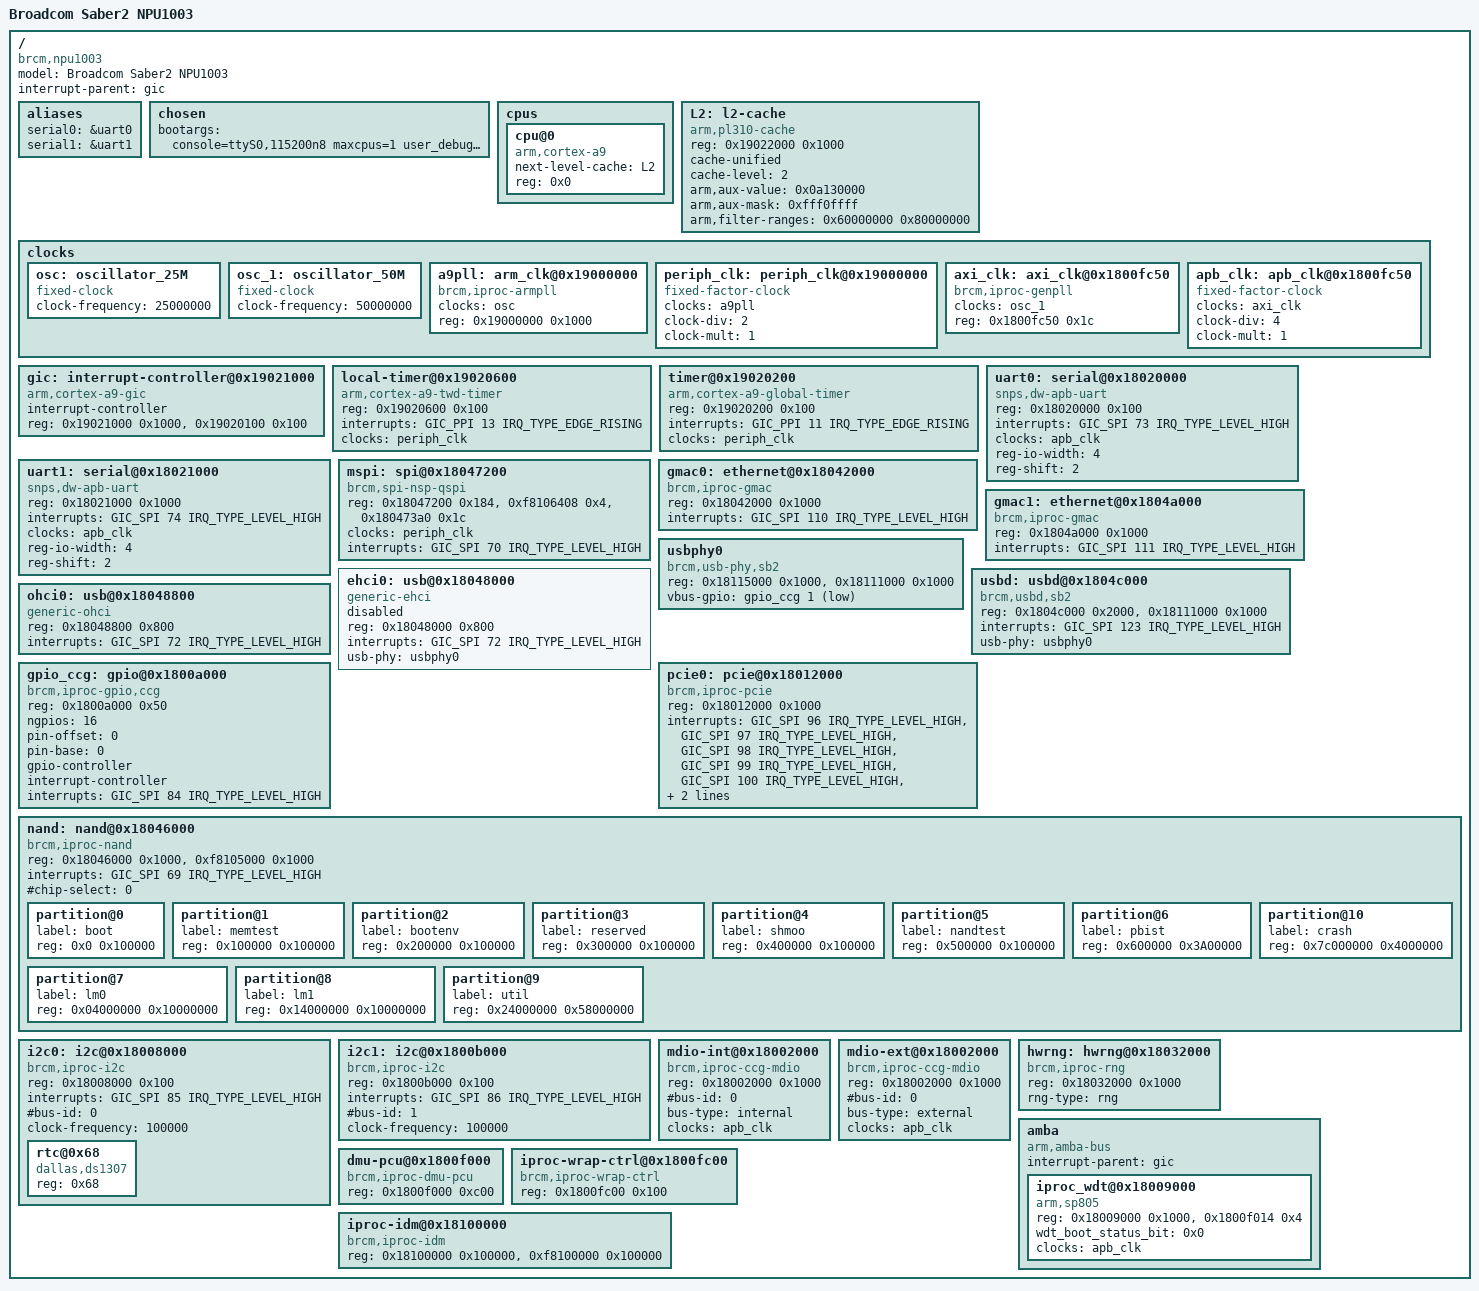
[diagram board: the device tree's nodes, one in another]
/*
 SB2 DTS
*/

/dts-v1/;

#include <dt-bindings/interrupt-controller/arm-gic.h>
#include <dt-bindings/gpio/gpio.h>
#include "skeleton.dtsi"

/ {
	model = "Broadcom Saber2 NPU1003";
	compatible = "brcm,npu1003", "brcm,iproc-p7";
	interrupt-parent = <&gic>;

	aliases {
		serial0 = &uart0;
		serial1 = &uart1;
	};

	chosen {
	bootargs = "console=ttyS0,115200n8 maxcpus=1 user_debug=31 envaddr=0xe0200000";
	};

	cpus {
		#address-cells = <1>;
		#size-cells = <0>;

		cpu@0 {
			device_type = "cpu";
			compatible = "arm,cortex-a9";
			next-level-cache = <&L2>;
			reg = <0x0>;
		};
	};

  	L2: l2-cache {
		compatible = "arm,pl310-cache";
		reg = <0x19022000 0x1000>;
		cache-unified;
		cache-level = <2>;
		/* aux register value */
		arm,aux-value = <0x0a130000>;
		arm,aux-mask = <0xfff0ffff>;
		arm,filter-ranges = <0x60000000 0x80000000>;
		/*arm,data-latency = <2 2 2>;*/
		/*arm,tag-latency = <1 1 1>;*/
	};

  	clocks {
		#address-cells = <1>;
		#size-cells = <1>;
		ranges;

		osc: oscillator_25M {
			#clock-cells = <0>;
			compatible = "fixed-clock";
			clock-frequency = <25000000>;
		};

		osc_1: oscillator_50M {
			#clock-cells = <0>;
			compatible = "fixed-clock";
			clock-frequency = <50000000>;
		};

		a9pll: arm_clk@0x19000000 {
			#clock-cells = <0>;
			compatible = "brcm,iproc-armpll";
			clocks = <&osc>;
			reg = <0x19000000 0x1000>;
		};

		periph_clk: periph_clk@0x19000000 {
			#clock-cells = <0>;
			compatible = "fixed-factor-clock";
			clocks = <&a9pll>;
			clock-div = <2>;
			clock-mult = <1>;
		};

		axi_clk: axi_clk@0x1800fc50 {
			#clock-cells = <0>;
			compatible = "brcm,iproc-genpll";
			clocks = <&osc_1>;
			reg = <0x1800fc50 0x1c>;
		};

		apb_clk: apb_clk@0x1800fc50 {
			#clock-cells = <0>;
			compatible = "fixed-factor-clock";
			clocks = <&axi_clk>;
			clock-div = <4>;
			clock-mult = <1>;
		};	
	};

	gic: interrupt-controller@0x19021000 {
		compatible = "arm,cortex-a9-gic";
		#interrupt-cells = <3>;
		interrupt-controller;
		reg = <0x19021000 0x1000>, <0x19020100 0x100>;
	};

	local-timer@0x19020600 {
		compatible = "arm,cortex-a9-twd-timer";
		reg = <0x19020600 0x100>;
		/* bits[15:8] PPI interrupt cpu mask. Each bit corresponds to each of the 8 possible cpus attached to the GIC*/
		interrupts = <GIC_PPI 13 IRQ_TYPE_EDGE_RISING>;
		clocks = <&periph_clk>;
	};

	timer@0x19020200 {
		compatible = "arm,cortex-a9-global-timer";
		reg = <0x19020200 0x100>;
		interrupts = <GIC_PPI 11 IRQ_TYPE_EDGE_RISING>; 
		clocks = <&periph_clk>;
	};

	uart0: serial@0x18020000 {
		compatible = "snps,dw-apb-uart";
		reg = <0x18020000 0x100>;
		interrupts = <GIC_SPI 73 IRQ_TYPE_LEVEL_HIGH>;
		/* clock-frequency = <100000000>; */
		clocks = <&apb_clk>;
		reg-io-width = <4>;
		reg-shift = <2>;
	};

	uart1: serial@0x18021000 {
		compatible = "snps,dw-apb-uart";
		reg = <0x18021000 0x1000>;
		interrupts = <GIC_SPI 74 IRQ_TYPE_LEVEL_HIGH>;
		clocks = <&apb_clk>;
		reg-io-width = <4>;
		reg-shift = <2>;
	};
		
	mspi: spi@0x18047200 {
		#address-cells = <1>;
		#size-cells = <0>;
		compatible = "brcm,spi-nsp-qspi", "brcm,spi-bcm-qspi";
    reg = <0x18047200 0x184>,
          <0xf8106408 0x4>,
          <0x180473a0 0x1c>;
    reg-names = "mspi", "intr_regs", "intr_status_reg";
		clocks = <&periph_clk>;
    interrupt-names = "mspi_done";
		interrupts = <GIC_SPI 70 IRQ_TYPE_LEVEL_HIGH>;
	};

	gmac0: ethernet@0x18042000 {
		compatible = "brcm,iproc-gmac";
		reg = <0x18042000 0x1000>;
		interrupts = <GIC_SPI 110 IRQ_TYPE_LEVEL_HIGH>;
	};

	gmac1: ethernet@0x1804a000 {
		compatible = "brcm,iproc-gmac";
		reg = <0x1804a000 0x1000>;
		interrupts = <GIC_SPI 111 IRQ_TYPE_LEVEL_HIGH>;
	};

	usbphy0: usbphy0 {
		#phy-cells = <0>;
		compatible = "brcm,usb-phy,sb2";
		reg = idm_usb2h: <0x18115000 0x1000>,
			idm_usb2d: <0x18111000 0x1000>;
		vbus-gpio = <&gpio_ccg 1 GPIO_ACTIVE_LOW>;
	};

	usbd: usbd@0x1804c000 {
		compatible = "brcm,usbd,sb2";
		reg = usb2d: <0x1804c000 0x2000>,
			idm_usb: <0x18111000 0x1000>;
		interrupts = <GIC_SPI 123 IRQ_TYPE_LEVEL_HIGH>;
		usb-phy = <&usbphy0>;
	};

	ehci0: usb@0x18048000 {
		compatible = "generic-ehci";
		reg = <0x18048000 0x800>;
		interrupts = <GIC_SPI 72 IRQ_TYPE_LEVEL_HIGH>;
		usb-phy = <&usbphy0>;
		/* for Device mode, set status to disabled or removing this node  */
		status = "disabled"; /*Note: no "enabled", but "okay" instead*/
	};
	
	ohci0: usb@0x18048800 {
		compatible = "generic-ohci";
		reg = <0x18048800 0x800>;
		interrupts = <GIC_SPI 72 IRQ_TYPE_LEVEL_HIGH>;
	};

	gpio_ccg: gpio@0x1800a000 {
		compatible = "brcm,iproc-gpio,ccg";
		reg = gpio: <0x1800a000 0x50>;
		ngpios = <16>;
		pin-offset = <0>;
		pin-base = <0>;
		gpio-controller;
		#gpio-cells = <2>;
		interrupt-controller;
		#interrupt-cells = <2>;
		interrupts = <GIC_SPI 84 IRQ_TYPE_LEVEL_HIGH>;
	};

	pcie0: pcie@0x18012000 {
		compatible = "brcm,iproc-pcie", "iproc-p7";
		reg = <0x18012000 0x1000>; /*<0x18032000 0x1000>; CCB MII management*/
		interrupts = <GIC_SPI 96 IRQ_TYPE_LEVEL_HIGH>,
			<GIC_SPI 97 IRQ_TYPE_LEVEL_HIGH>,
			<GIC_SPI 98 IRQ_TYPE_LEVEL_HIGH>,
			<GIC_SPI 99 IRQ_TYPE_LEVEL_HIGH>,
			<GIC_SPI 100 IRQ_TYPE_LEVEL_HIGH>,
			<GIC_SPI 101 IRQ_TYPE_LEVEL_HIGH>;
		status = "okay";
		#address-cells = <2>;
		#size-cells = <2>;
		device_type = "pci";
		/*non-prefetchable mem space, pcie addr 0x0 0x20000000, cpu addr 0x20000000, size 0x0 0x20000000*/
		ranges = <0x82000000 0 0x20000000 0x20000000 0 0x20000000>;
		phy-addr = <0>;
	};

	nand: nand@0x18046000 {
		compatible = "brcm,iproc-nand";
		reg =	nand_regs: <0x18046000 0x1000>,
			nand_idm_regs: <0xf8105000 0x1000>;
		interrupts = <GIC_SPI 69 IRQ_TYPE_LEVEL_HIGH>;
		#chip-select = <0>;
		#address-cells = <1>;
		#size-cells = <1>;
		partition@0 {
			label = "boot";
			reg = <0x0 0x100000>;
		};
		partition@1 {
			label = "memtest";
			reg = <0x100000 0x100000>;
		};
		partition@2 {
			label = "bootenv";
			reg = <0x200000 0x100000>;
		};
		partition@3 {
			label = "reserved";
			reg = <0x300000 0x100000>;
		};
		partition@4 {
			label = "shmoo";
			reg = <0x400000 0x100000>;
		};		
		partition@5 {
			label = "nandtest";
			reg = <0x500000 0x100000>;
		};
		partition@6 {
			label = "pbist";
			reg = <0x600000 0x3A00000>;
		};
		partition@7 {
			label = "lm0";
			reg = <0x04000000 0x10000000>;
		};
		partition@8 {
			label = "lm1";
			reg = <0x14000000 0x10000000>;
		};
		partition@9 {
			label = "util";
			reg = <0x24000000 0x58000000>;
		};
		partition@10 {
			label = "crash";
			reg = <0x7c000000 0x4000000>;
		};
	};

	i2c0: i2c@0x18008000 {
		compatible = "brcm,iproc-i2c";
		reg = <0x18008000 0x100>;
		interrupts = <GIC_SPI 85 IRQ_TYPE_LEVEL_HIGH>;
		#bus-id = <0>;
		clock-frequency = <100000>;
	
		#address-cells = <1>;
		#size-cells = <0>;

		rtc@0x68 {
			compatible = "dallas,ds1307";
			reg = <0x68>;
		};
	};

	i2c1: i2c@0x1800b000 {
		compatible = "brcm,iproc-i2c";
		reg = <0x1800b000 0x100>;
		interrupts = <GIC_SPI 86 IRQ_TYPE_LEVEL_HIGH>;
		#bus-id = <1>;
		clock-frequency = <100000>;
	};

	mdio-int@0x18002000 {
		compatible = "brcm,iproc-ccg-mdio";
		#address-cells = <1>;
		#size-cells = <1>;
		reg = <0x18002000 0x1000>;
		#bus-id = <0>;
		bus-type = "internal";
		clocks = <&apb_clk>;
		clock-names = "apb_clk";
	};

	mdio-ext@0x18002000 {
		compatible = "brcm,iproc-ccg-mdio";
		#address-cells = <1>;
		#size-cells = <1>;
		reg = <0x18002000 0x1000>;
		#bus-id = <0>;
		bus-type = "external";
		clocks = <&apb_clk>;
		clock-names = "apb_clk";
	};

	hwrng: hwrng@0x18032000 {
		compatible = "brcm,iproc-rng";
		#address-cells = <1>;
		#size-cells = <1>;
		reg = <0x18032000 0x1000>;
		rng-type = "rng";
	};

	amba {
		#address-cells = <1>;
		#size-cells = <1>;
		compatible = "arm,amba-bus", "simple-bus";
		interrupt-parent = <&gic>;
		ranges;

		iproc_wdt@0x18009000 {
			compatible = "arm,sp805", "arm,primecell";
			reg = iproc_wdt_base: <0x18009000 0x1000>,
	      		iproc_reset_reg: <0x1800f014 0x4>;
	      	wdt_boot_status_bit = <0x0>;	
			clocks = <&apb_clk>;
			clock-names = "apb_pclk"; /*should be "apb_pclk" according to Documentation/devicetree/bindings/arm/primecell.txt*/
		};
	};

	dmu-pcu@0x1800f000 {
		compatible = "brcm,iproc-dmu-pcu";
		#address-cells = <1>;
		#size-cells = <1>;
		reg = <0x1800f000 0xc00>;
	};

	iproc-wrap-ctrl@0x1800fc00 {
		compatible = "brcm,iproc-wrap-ctrl";
		#address-cells = <1>;
		#size-cells = <1>;
		reg = <0x1800fc00 0x100>;
	};

	iproc-idm@0x18100000 {
		compatible = "brcm,iproc-idm";
		#address-cells = <1>;
		#size-cells = <1>;
		reg = idm0: <0x18100000 0x100000>,
			  idm1: <0xf8100000 0x100000>;
	};
};
